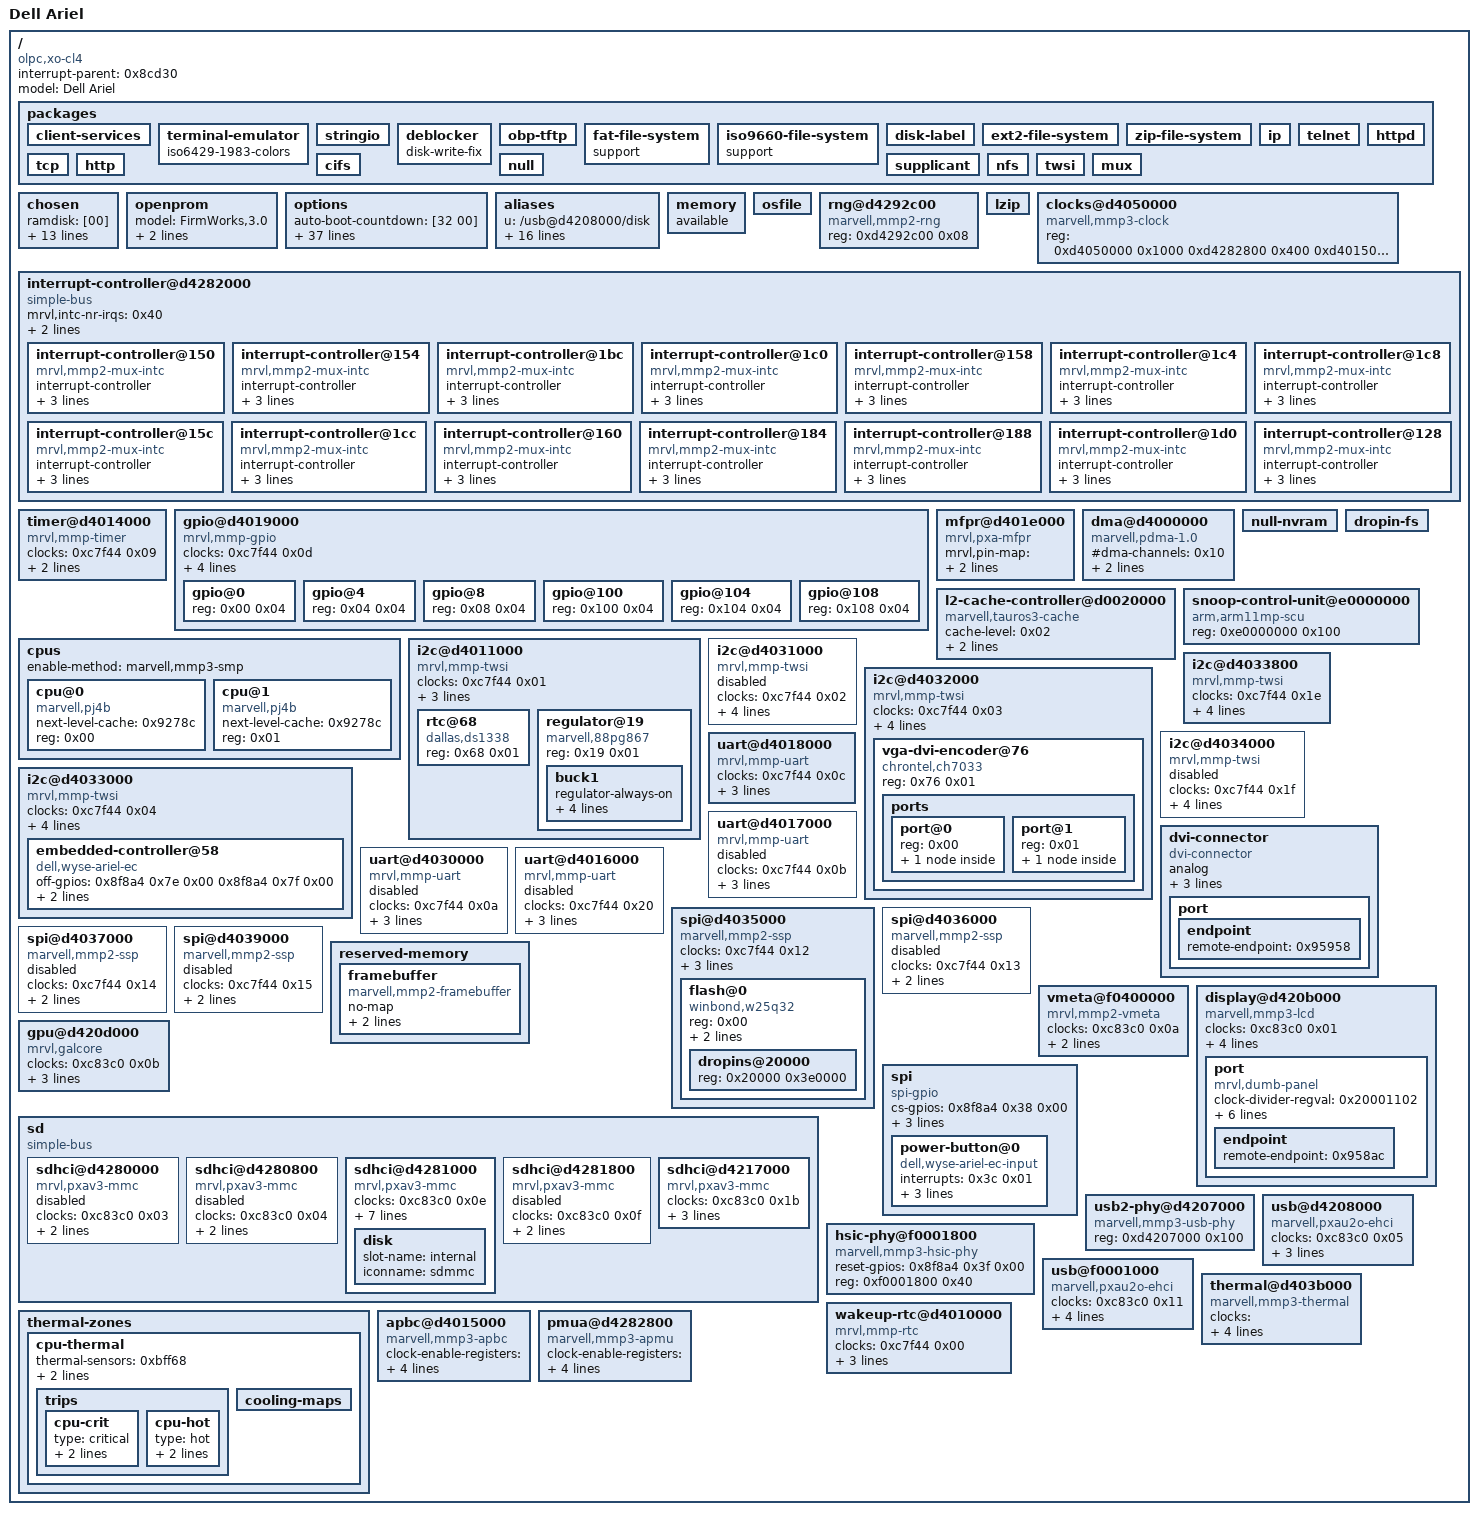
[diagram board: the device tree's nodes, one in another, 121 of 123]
/dts-v1/;

/ {
	phandle = <0x2d294>;
	ranges;
	interrupt-parent = <0x8cd30>;
	compatible = "olpc,xo-cl4\0dell,wyse-ariel\0marvell,mmp3";
	model = "Dell Ariel";
	#size-cells = <0x01>;
	#address-cells = <0x01>;

	packages {
		phandle = <0x313a8>;

		client-services {
			phandle = <0x313dc>;
		};

		terminal-emulator {
			phandle = <0x3c800>;
			iso6429-1983-colors;
		};

		stringio {
			phandle = <0x3f680>;
		};

		deblocker {
			phandle = <0x40a44>;
			disk-write-fix;
		};

		obp-tftp {
			phandle = <0x420f8>;
		};

		fat-file-system {
			phandle = <0x4fd80>;
			support;
		};

		iso9660-file-system {
			phandle = <0x55284>;
			support;
		};

		disk-label {
			phandle = <0x56110>;
		};

		ext2-file-system {
			phandle = <0x5f07c>;
		};

		zip-file-system {
			phandle = <0x65644>;
		};

		ip {
			phandle = <0x69f10>;
		};

		telnet {
			phandle = <0x6cb8c>;
		};

		httpd {
			phandle = <0x6db10>;
		};

		tcp {
			phandle = <0x70740>;
		};

		http {
			phandle = <0x75e9c>;
		};

		cifs {
			phandle = <0x76bb4>;
		};

		supplicant {
			phandle = <0x7a478>;
		};

		null {
			phandle = <0x84554>;
		};

		nfs {
			phandle = <0x84afc>;
		};

		twsi {
			phandle = <0x906b0>;
		};

		mux {
			phandle = <0x91750>;
		};
	};

	chosen {
		phandle = <0x31448>;
		ramdisk = [00];
		cpu = <0x00>;
		root-path = [00];
		vendor-options = [00];
		client-name = [00];
		tftp-file = [00];
		domain-name = [00];
		bootargs = [00];
		bootpath = [00];
		nvram = <0x00>;
		mmu = <0x00>;
		memory = <0x00>;
		clock = <0x00>;
		stdout-#lines = <0x00>;
		#address-cells = <0x01>;
		#size-cells = <0x01>;
		ranges;
	};

	openprom {
		phandle = <0x314ec>;
		model = "FirmWorks,3.0";
		aligned-allocator;
		relative-addressing;
	};

	options {
		phandle = <0x31580>;
		auto-boot-countdown = [32 00];
		ramdisk = [00];
		usb-delay = "350";
		menu? = "true";
		http-proxy = [00];
		client-symbols? = "false";
		fcode-debug? = "true";
		ip-address = "dhcp";
		ip-router = [00];
		ip-domain = [00];
		ip-netmask = "255.255.255.0";
		ip-dns-server = [00];
		local-mac-address? = "true";
		oem-logo;
		oem-logo? = "false";
		oem-banner = [00];
		oem-banner? = "false";
		output-device = "screen";
		input-device = "keyboard";
		load-base = "201326592";
		boot-command = "boot";
		auto-boot? = "true";
		watchdog-reboot? = "false";
		diag-file = [00];
		diag-device = "net";
		boot-file = [00];
		boot-device = "u:\\boot\\olpc.fth int:\\boot\\olpc.fth net";
		ansi-terminal? = "true";
		screen-#columns = "999";
		screen-#rows = "999";
		silent-mode? = "false";
		use-nvramrc? = "false";
		nvramrc = [00];
		security-password;
		security-#badlogins = [30 00];
		security-mode = "none";
		diag-switch? = "false";
	};

	aliases {
		phandle = <0x315cc>;
		u = "/usb@d4208000/disk";
		int = "/sd/sdhci@d4281000/disk";
		screen = "/display";
		dropins = "/dropins";
		serial2 = "/uart@d4018000";
		i2c5 = "/i2c@d4033000";
		i2c4 = "/i2c@d4033800";
		i2c3 = "/i2c@d4032000";
		i2c2 = "/i2c@d4011000";
		rom = "/dropin-fs";
		nfs = "net//obp-tftp:last//nfs";
		cifs = "tcp//cifs";
		smb = "tcp//cifs";
		httpd = "tcp//httpd:verbose";
		http = "tcp//http";
		tcp = "ip//tcp";
		ip = "//ip";
	};

	memory {
		phandle = <0x5d8b4>;
		available;
		device_type = "memory";
	};

	osfile {
		phandle = <0x66a2c>;
	};

	rng@d4292c00 {
		phandle = <0x69730>;
		reg = <0xd4292c00 0x08>;
		compatible = "marvell,mmp2-rng";
	};

	lzip {
		phandle = <0x69cf8>;
	};

	clocks@d4050000 {
		phandle = <0x8c2cc>;
		#power-domain-cells = <0x01>;
		#reset-cells = <0x01>;
		#clock-cells = <0x01>;
		reg-names = "mpmu\0apmu\0apbc";
		reg = <0xd4050000 0x1000 0xd4282800 0x400 0xd4015000 0x1000>;
		compatible = "marvell,mmp3-clock\0marvell,mmp2-clock";
	};

	interrupt-controller@d4282000 {
		phandle = <0x8cd30>;
		mrvl,intc-nr-irqs = <0x40>;
		#interrupt-cells = <0x01>;
		interrupt-controller;
		#size-cells = <0x01>;
		#address-cells = <0x01>;
		ranges;
		compatible = "simple-bus\0mrvl,mmp3-intc\0marvell,mmp3-intc";
		reg = <0xd4282000 0x1000 0xd4284000 0x100>;

		interrupt-controller@150 {
			phandle = <0x8d2e4>;
			reg-names = "mux status\0mux mask";
			#interrupt-cells = <0x01>;
			interrupt-controller;
			compatible = "mrvl,mmp2-mux-intc";
			reg = <0x150 0x04 0x168 0x04>;
			interrupts = <0x04>;
			mrvl,intc-nr-irqs = <0x04>;
		};

		interrupt-controller@154 {
			phandle = <0x8d458>;
			reg-names = "mux status\0mux mask";
			#interrupt-cells = <0x01>;
			interrupt-controller;
			compatible = "mrvl,mmp2-mux-intc";
			reg = <0x154 0x04 0x16c 0x04>;
			interrupts = <0x05>;
			mrvl,intc-nr-irqs = <0x02>;
		};

		interrupt-controller@1bc {
			phandle = <0x8d5cc>;
			reg-names = "mux status\0mux mask";
			#interrupt-cells = <0x01>;
			interrupt-controller;
			compatible = "mrvl,mmp2-mux-intc";
			reg = <0x1bc 0x04 0x1a4 0x04>;
			interrupts = <0x06>;
			mrvl,intc-nr-irqs = <0x03>;
		};

		interrupt-controller@1c0 {
			phandle = <0x8d740>;
			reg-names = "mux status\0mux mask";
			#interrupt-cells = <0x01>;
			interrupt-controller;
			compatible = "mrvl,mmp2-mux-intc";
			reg = <0x1c0 0x04 0x1a8 0x04>;
			interrupts = <0x08>;
			mrvl,intc-nr-irqs = <0x04>;
		};

		interrupt-controller@158 {
			phandle = <0x8d8b4>;
			reg-names = "mux status\0mux mask";
			#interrupt-cells = <0x01>;
			interrupt-controller;
			compatible = "mrvl,mmp2-mux-intc";
			reg = <0x158 0x04 0x170 0x04>;
			interrupts = <0x11>;
			mrvl,intc-nr-irqs = <0x05>;
		};

		interrupt-controller@1c4 {
			phandle = <0x8da28>;
			reg-names = "mux status\0mux mask";
			#interrupt-cells = <0x01>;
			interrupt-controller;
			compatible = "mrvl,mmp2-mux-intc";
			reg = <0x1c4 0x04 0x1ac 0x04>;
			interrupts = <0x12>;
			mrvl,intc-nr-irqs = <0x03>;
		};

		interrupt-controller@1c8 {
			phandle = <0x8db9c>;
			reg-names = "mux status\0mux mask";
			#interrupt-cells = <0x01>;
			interrupt-controller;
			compatible = "mrvl,mmp2-mux-intc";
			reg = <0x1c8 0x04 0x1b0 0x04>;
			interrupts = <0x1e>;
			mrvl,intc-nr-irqs = <0x02>;
		};

		interrupt-controller@15c {
			phandle = <0x8dd10>;
			reg-names = "mux status\0mux mask";
			#interrupt-cells = <0x01>;
			interrupt-controller;
			compatible = "mrvl,mmp2-mux-intc";
			reg = <0x15c 0x04 0x174 0x04>;
			interrupts = <0x23>;
			mrvl,intc-nr-irqs = <0x1f>;
		};

		interrupt-controller@1cc {
			phandle = <0x8de84>;
			reg-names = "mux status\0mux mask";
			#interrupt-cells = <0x01>;
			interrupt-controller;
			compatible = "mrvl,mmp2-mux-intc";
			reg = <0x1cc 0x04 0x1b4 0x04>;
			interrupts = <0x2a>;
			mrvl,intc-nr-irqs = <0x02>;
		};

		interrupt-controller@160 {
			phandle = <0x8dff8>;
			reg-names = "mux status\0mux mask";
			#interrupt-cells = <0x01>;
			interrupt-controller;
			compatible = "mrvl,mmp2-mux-intc";
			reg = <0x160 0x04 0x178 0x04>;
			interrupts = <0x33>;
			mrvl,intc-nr-irqs = <0x02>;
		};

		interrupt-controller@184 {
			phandle = <0x8e16c>;
			reg-names = "mux status\0mux mask";
			#interrupt-cells = <0x01>;
			interrupt-controller;
			compatible = "mrvl,mmp2-mux-intc";
			reg = <0x184 0x04 0x17c 0x04>;
			interrupts = <0x37>;
			mrvl,intc-nr-irqs = <0x04>;
		};

		interrupt-controller@188 {
			phandle = <0x8e2e0>;
			reg-names = "mux status\0mux mask";
			#interrupt-cells = <0x01>;
			interrupt-controller;
			compatible = "mrvl,mmp2-mux-intc";
			reg = <0x188 0x04 0x180 0x04>;
			interrupts = <0x39>;
			mrvl,intc-nr-irqs = <0x14>;
		};

		interrupt-controller@1d0 {
			phandle = <0x8e454>;
			reg-names = "mux status\0mux mask";
			#interrupt-cells = <0x01>;
			interrupt-controller;
			compatible = "mrvl,mmp2-mux-intc";
			reg = <0x1d0 0x04 0x1b8 0x04>;
			interrupts = <0x3a>;
			mrvl,intc-nr-irqs = <0x05>;
		};

		interrupt-controller@128 {
			phandle = <0x8e5c8>;
			reg-names = "mux status\0mux mask";
			#interrupt-cells = <0x01>;
			interrupt-controller;
			compatible = "mrvl,mmp2-mux-intc";
			reg = <0x128 0x04 0x11c 0x04>;
			interrupts = <0x30>;
			mrvl,intc-nr-irqs = <0x18>;
		};
	};

	timer@d4014000 {
		phandle = <0x8f31c>;
		clocks = <0xc7f44 0x09>;
		interrupts = <0x0d>;
		reg = <0xd4014000 0x100>;
		compatible = "mrvl,mmp-timer";
	};

	gpio@d4019000 {
		phandle = <0x8f8a4>;
		clocks = <0xc7f44 0x0d>;
		#size-cells = <0x01>;
		#address-cells = <0x01>;
		clock-names = "GPIO";
		ranges;
		#interrupt-cells = <0x02>;
		interrupt-controller;
		#gpio-cells = <0x02>;
		gpio-controller;
		interrupt-names = "gpio_mux";
		interrupts = <0x31>;
		reg = <0xd4019000 0x1000>;
		compatible = "mrvl,mmp-gpio\0\0marvell,mmp2-gpio";

		gpio@0 {
			phandle = <0x8fb60>;
			reg = <0x00 0x04>;
		};

		gpio@4 {
			phandle = <0x8fbc4>;
			reg = <0x04 0x04>;
		};

		gpio@8 {
			phandle = <0x8fc28>;
			reg = <0x08 0x04>;
		};

		gpio@100 {
			phandle = <0x8fc8c>;
			reg = <0x100 0x04>;
		};

		gpio@104 {
			phandle = <0x8fcf0>;
			reg = <0x104 0x04>;
		};

		gpio@108 {
			phandle = <0x8fd54>;
			reg = <0x108 0x04>;
		};
	};

	mfpr@d401e000 {
		phandle = <0x902ac>;
		mrvl,pin-map = <0x00 0x3a 0x54 0x3b 0x49 0x280 0x4a 0x65 0x170 0x66 0x67 0x00 0x68 0xffffffff 0x1fc 0x69 0xffffffff 0x1f8 0x6a 0xffffffff 0x1f4 0x6b 0xffffffff 0x1f0 0x6c 0xffffffff 0x21c 0x6d 0xffffffff 0x218 0x6e 0xffffffff 0x214 0x6f 0xffffffff 0x200 0x70 0xffffffff 0x244 0x71 0xffffffff 0x25c 0x72 0xffffffff 0x164 0x73 0x7a 0x260 0x7b 0xffffffff 0x148 0x7c 0x8d 0x0c 0x8e 0xffffffff 0x08 0x8f 0x97 0x220 0x98 0x98 0x248 0x9a 0x9b 0x254 0x9c 0x9f 0x14c 0xa0 0xffffffff 0x250 0xa1 0xffffffff 0x210 0xa2 0xffffffff 0x20c 0xa3 0xffffffff 0x208 0xa4 0xffffffff 0x204 0xa5 0xffffffff 0x1ec 0xa6 0xffffffff 0x1e8 0xa7 0xffffffff 0x1e4 0xa8 0xffffffff 0x1e0 0xa9 0xaa 0x2c0 0xab 0xffffffff 0x2c8 0x15b 0x15c 0x140 0x15d 0x15e 0x2bc 0x159 0xffffffff 0x2c4 0x15f 0xffffffff 0x160 0xffffffff 0xffffffff 0xffffffff>;
		compatible = "mrvl,pxa-mfpr";
		reg = <0xd401e000 0x1000>;
	};

	dma@d4000000 {
		phandle = <0x905dc>;
		#dma-channels = <0x10>;
		interrupts = <0x30>;
		compatible = "marvell,pdma-1.0";
		reg = <0xd4000000 0x400>;
	};

	null-nvram {
		phandle = <0x92158>;
	};

	dropin-fs {
		phandle = <0x922e0>;
	};

	l2-cache-controller@d0020000 {
		phandle = <0x9278c>;
		cache-level = <0x02>;
		cache-unified;
		reg = <0xd0020000 0x1000>;
		compatible = "marvell,tauros3-cache\0arm,pl310-cache";
	};

	cpus {
		phandle = <0x928a4>;
		enable-method = "marvell,mmp3-smp";
		#size-cells = <0x00>;
		#address-cells = <0x01>;

		cpu@0 {
			phandle = <0x929b8>;
			next-level-cache = <0x9278c>;
			reg = <0x00>;
			compatible = "marvell,pj4b";
			device_type = "cpu";
		};

		cpu@1 {
			phandle = <0x92ab4>;
			next-level-cache = <0x9278c>;
			reg = <0x01>;
			compatible = "marvell,pj4b";
			device_type = "cpu";
		};
	};

	snoop-control-unit@e0000000 {
		phandle = <0x92c24>;
		reg = <0xe0000000 0x100>;
		compatible = "arm,arm11mp-scu";
	};

	i2c@d4011000 {
		phandle = <0x92e3c>;
		clocks = <0xc7f44 0x01>;
		#size-cells = <0x01>;
		#address-cells = <0x01>;
		reg = <0xd4011000 0x70>;
		interrupts = <0x07>;
		mrvl,i2c-fast-mode;
		compatible = "mrvl,mmp-twsi";

		rtc@68 {
			phandle = <0x94814>;
			reg = <0x68 0x01>;
			compatible = "dallas,ds1338\0idt,idt1338-rtc";
		};

		regulator@19 {
			phandle = <0x94ef8>;
			reg = <0x19 0x01>;
			compatible = "marvell,88pg867";

			buck1 {
				phandle = <0x94ff0>;
				regulator-always-on;
				regulator-boot-on;
				regulator-max-microvolt = <0x1b7740>;
				regulator-min-microvolt = <0x1b7740>;
				regulator-name = "vdd_1v8";
			};
		};
	};

	i2c@d4031000 {
		phandle = <0x93264>;
		clocks = <0xc7f44 0x02>;
		status = "disabled";
		#size-cells = <0x01>;
		#address-cells = <0x01>;
		reg = <0xd4031000 0x70>;
		interrupts = <0x00>;
		interrupt-parent = <0x8d8b4>;
		mrvl,i2c-fast-mode;
		compatible = "mrvl,mmp-twsi";
	};

	i2c@d4032000 {
		phandle = <0x936b4>;
		clocks = <0xc7f44 0x03>;
		#size-cells = <0x01>;
		#address-cells = <0x01>;
		reg = <0xd4032000 0x70>;
		interrupts = <0x01>;
		interrupt-parent = <0x8d8b4>;
		mrvl,i2c-fast-mode;
		compatible = "mrvl,mmp-twsi";

		vga-dvi-encoder@76 {
			phandle = <0x95138>;
			reg = <0x76 0x01>;
			compatible = "chrontel,ch7033";

			ports {
				phandle = <0x95780>;
				#size-cells = <0x00>;
				#address-cells = <0x01>;

				port@0 {
					phandle = <0x95864>;
					reg = <0x00>;

					endpoint {
						phandle = <0x958ac>;
						remote-endpoint = <0x997bc>;
					};
				};

				port@1 {
					phandle = <0x95910>;
					reg = <0x01>;

					endpoint {
						phandle = <0x95958>;
						remote-endpoint = <0x960b4>;
					};
				};
			};
		};
	};

	i2c@d4033000 {
		phandle = <0x93b04>;
		clocks = <0xc7f44 0x04>;
		#size-cells = <0x01>;
		#address-cells = <0x01>;
		reg = <0xd4033000 0x70>;
		interrupts = <0x02>;
		interrupt-parent = <0x8d8b4>;
		mrvl,i2c-fast-mode;
		compatible = "mrvl,mmp-twsi";

		embedded-controller@58 {
			phandle = <0x95a2c>;
			off-gpios = <0x8f8a4 0x7e 0x00 0x8f8a4 0x7f 0x00>;
			system-power-controller;
			reg = <0x58 0x01>;
			compatible = "dell,wyse-ariel-ec\0ene,kb3930";
		};
	};

	i2c@d4033800 {
		phandle = <0x93f54>;
		clocks = <0xc7f44 0x1e>;
		#size-cells = <0x01>;
		#address-cells = <0x01>;
		reg = <0xd4033800 0x70>;
		interrupts = <0x03>;
		interrupt-parent = <0x8d8b4>;
		mrvl,i2c-fast-mode;
		compatible = "mrvl,mmp-twsi";
	};

	i2c@d4034000 {
		phandle = <0x943a4>;
		clocks = <0xc7f44 0x1f>;
		status = "disabled";
		#size-cells = <0x01>;
		#address-cells = <0x01>;
		reg = <0xd4034000 0x70>;
		interrupts = <0x04>;
		interrupt-parent = <0x8d8b4>;
		mrvl,i2c-fast-mode;
		compatible = "mrvl,mmp-twsi";
	};

	dvi-connector {
		phandle = <0x95fa8>;
		analog;
		digital;
		hpd-gpios = <0x8f8a4 0x3e 0x01>;
		ddc-i2c-bus = <0x93f54>;
		compatible = "dvi-connector";

		port {
			phandle = <0x96084>;

			endpoint {
				phandle = <0x960b4>;
				remote-endpoint = <0x95958>;
			};
		};
	};

	uart@d4018000 {
		phandle = <0x96178>;
		clocks = <0xc7f44 0x0c>;
		interrupts = <0x18>;
		reg-shift = <0x02>;
		reg = <0xd4018000 0x20>;
		compatible = "mrvl,mmp-uart\0intel,xscale-uart";
	};

	uart@d4017000 {
		phandle = <0x9636c>;
		clocks = <0xc7f44 0x0b>;
		status = "disabled";
		interrupts = <0x1c>;
		reg-shift = <0x02>;
		reg = <0xd4017000 0x20>;
		compatible = "mrvl,mmp-uart\0intel,xscale-uart";
	};

	uart@d4030000 {
		phandle = <0x96560>;
		clocks = <0xc7f44 0x0a>;
		status = "disabled";
		interrupts = <0x1b>;
		reg-shift = <0x02>;
		reg = <0xd4030000 0x20>;
		compatible = "mrvl,mmp-uart\0intel,xscale-uart";
	};

	uart@d4016000 {
		phandle = <0x96754>;
		clocks = <0xc7f44 0x20>;
		status = "disabled";
		interrupts = <0x2e>;
		reg-shift = <0x02>;
		reg = <0xd4016000 0x20>;
		compatible = "mrvl,mmp-uart\0intel,xscale-uart";
	};

	spi@d4035000 {
		phandle = <0x97cdc>;
		clocks = <0xc7f44 0x12>;
		cs-gpios = <0x8f8a4 0x2e 0x01>;
		compatible = "marvell,mmp2-ssp";
		#size-cells = <0x00>;
		#address-cells = <0x01>;
		reg = <0xd4035000 0x1000>;
		interrupts = <0x00>;

		flash@0 {
			phandle = <0x98304>;
			#address-cells = <0x01>;
			reg = <0x00>;
			m25p,fast-read;
			spi-max-frequency = <0x632ea00>;
			compatible = "winbond,w25q32\0jedec,spi-nor";

			dropins@20000 {
				phandle = <0x98940>;
				reg = <0x20000 0x3e0000>;
			};
		};
	};

	spi@d4036000 {
		phandle = <0x97e5c>;
		clocks = <0xc7f44 0x13>;
		status = "disabled";
		compatible = "marvell,mmp2-ssp";
		#size-cells = <0x00>;
		#address-cells = <0x01>;
		reg = <0xd4036000 0x1000>;
		interrupts = <0x01>;
	};

	spi@d4037000 {
		phandle = <0x97fdc>;
		clocks = <0xc7f44 0x14>;
		status = "disabled";
		compatible = "marvell,mmp2-ssp";
		#size-cells = <0x00>;
		#address-cells = <0x01>;
		reg = <0xd4037000 0x1000>;
		interrupts = <0x14>;
	};

	spi@d4039000 {
		phandle = <0x9815c>;
		clocks = <0xc7f44 0x15>;
		status = "disabled";
		compatible = "marvell,mmp2-ssp";
		#size-cells = <0x00>;
		#address-cells = <0x01>;
		reg = <0xd4039000 0x1000>;
		interrupts = <0x15>;
	};

	reserved-memory {
		phandle = <0x99280>;
		ranges;
		#size-cells = <0x01>;
		#address-cells = <0x01>;

		framebuffer {
			phandle = <0x99318>;
			no-map;
			alignment = <0x2000000>;
			size = <0x2000000>;
			compatible = "marvell,mmp2-framebuffer\0marvell,armada-framebuffer";
		};
	};

	vmeta@f0400000 {
		phandle = <0x99440>;
		clocks = <0xc83c0 0x0a>;
		interrupts = <0x1a>;
		clock-names = "VMETACLK";
		compatible = "mrvl,mmp2-vmeta";
		reg = <0xf0400000 0x400000>;
	};

	display@d420b000 {
		phandle = <0x99640>;
		clock-names = "LCDCLK";
		clocks = <0xc83c0 0x01>;
		iso6429-1983-colors;
		character-set = "ISO8859-1";
		device_type = "display";
		interrupts = <0x29>;
		compatible = "marvell,mmp3-lcd\0marvell,armada-lcdc\0mrvl,pxa168fb";
		reg = <0xd420b000 0x1000>;

		port {
			phandle = <0x9978c>;
			clock-divider-regval = <0x20001102>;
			lcd-pn-ctrl0-regval = <0x8041100>;
			lcd-dumb-ctrl-regval = <0x6000000d>;
			linux,mode-names = "1200x900@50";
			linux,timing-modes = <0x400 0x300 0x32 0x364aed0 0xa0 0x18 0x1d 0x03 0x88 0x06 0x00 0x98 0x73>;
			model = "OLPC DCON panel";
			compatible = "mrvl,dumb-panel";

			endpoint {
				phandle = <0x997bc>;
				remote-endpoint = <0x958ac>;
			};
		};
	};

	gpu@d420d000 {
		phandle = <0x9b5c4>;
		clocks = <0xc83c0 0x0b>;
		clock-names = "GCCLK";
		interrupt-names = "galcore 3D\0galcore 2D";
		interrupt-parent = <0x8d740>;
		interrupts = <0x00 0x02>;
		reg = <0xd420d000 0x1000>;
		compatible = "mrvl,galcore";
	};

	sd {
		phandle = <0x9b718>;
		ranges = <0xd4280000 0xd4280000 0x2000 0xd4217000 0xd4217000 0x800>;
		compatible = "simple-bus\0sdhci";
		#size-cells = <0x01>;
		#address-cells = <0x01>;

		sdhci@d4280000 {
			phandle = <0x9f95c>;
			clocks = <0xc83c0 0x03>;
			status = "disabled";
			#size-cells = <0x00>;
			#address-cells = <0x00>;
			clock-names = "io";
			interrupts = <0x27>;
			compatible = "mrvl,pxav3-mmc\0sdhci-pxav3";
			reg = <0xd4280000 0x800>;
		};

		sdhci@d4280800 {
			phandle = <0xa0068>;
			clocks = <0xc83c0 0x04>;
			status = "disabled";
			#size-cells = <0x00>;
			#address-cells = <0x00>;
			clock-names = "io";
			interrupts = <0x34>;
			compatible = "mrvl,pxav3-mmc\0sdhci-pxav3";
			reg = <0xd4280800 0x800>;
		};

		sdhci@d4281000 {
			phandle = <0xa0774>;
			clocks = <0xc83c0 0x0e>;
			cap-mmc-highspeed;
			bus-width = <0x08>;
			non-removable;
			max-frequency = <0x2faf080>;
			clk-delay-cycles = <0x0f>;
			#size-cells = <0x00>;
			#address-cells = <0x00>;
			clock-names = "io";
			interrupts = <0x35>;
			compatible = "mrvl,pxav3-mmc\0sdhci-pxav3";
			reg = <0xd4281000 0x800>;

			disk {
				phandle = <0xa1e48>;
				slot-name = "internal";
				device_type = "block";
				iconname = "sdmmc";
			};
		};

		sdhci@d4281800 {
			phandle = <0xa0e80>;
			clocks = <0xc83c0 0x0f>;
			status = "disabled";
			#size-cells = <0x00>;
			#address-cells = <0x00>;
			clock-names = "io";
			interrupts = <0x36>;
			compatible = "mrvl,pxav3-mmc\0sdhci-pxav3";
			reg = <0xd4281800 0x800>;
		};

		sdhci@d4217000 {
			phandle = <0xa158c>;
			clocks = <0xc83c0 0x1b>;
			#size-cells = <0x00>;
			#address-cells = <0x00>;
			clock-names = "io";
			interrupts = <0x00>;
			interrupt-parent = <0x8e16c>;
			compatible = "mrvl,pxav3-mmc\0sdhci-pxav3";
			reg = <0xd4217000 0x800>;
		};
	};

	spi {
		phandle = <0xa2c7c>;
		cs-gpios = <0x8f8a4 0x38 0x00>;
		gpio-mosi = <0x8f8a4 0x3a 0x00>;
		gpio-miso = <0x8f8a4 0x39 0x00>;
		gpio-sck = <0x8f8a4 0x37 0x00>;
		#size-cells = <0x00>;
		#address-cells = <0x01>;
		compatible = "spi-gpio";

		power-button@0 {
			phandle = <0xa2e24>;
			interrupts = <0x3c 0x01>;
			interrupt-parent = <0x8f8a4>;
			spi-max-frequency = <0x1f78a40>;
			compatible = "dell,wyse-ariel-ec-input\0ene,kb3930-input";
			reg = <0x00>;
		};
	};

	usb2-phy@d4207000 {
		phandle = <0xa4624>;
		#phy-cells = <0x00>;
		compatible = "marvell,mmp3-usb-phy\0mrvl,mmp3-usb2phy";
		reg = <0xd4207000 0x100>;
	};

	usb@d4208000 {
		phandle = <0xa4a18>;
		clocks = <0xc83c0 0x05>;
		reg-names = "u2o";
		compatible = "marvell,pxau2o-ehci\0usb-ehci";
		device_type = "ehci";
		#size-cells = <0x00>;
		#address-cells = <0x02>;
		phys = <0xa4624>;
		phy-names = "usb";
		interrupts = <0x2c>;
		clock-names = "USBCLK";
		reg = <0xd4208000 0x200>;
	};

	hsic-phy@f0001800 {
		phandle = <0xb1984>;
		reset-gpios = <0x8f8a4 0x3f 0x00>;
		compatible = "marvell,mmp3-hsic-phy";
		#phy-cells = <0x00>;
		reg = <0xf0001800 0x40>;
	};

	usb@f0001000 {
		phandle = <0xb1bc8>;
		clocks = <0xc83c0 0x11>;
		phys = <0xb1984>;
		phy-names = "usb";
		phy_type = "hsic";
		interrupts = <0x16>;
		clock-names = "USBCLK";
		compatible = "marvell,pxau2o-ehci\0usb-ehci";
		device_type = "ehci";
		#size-cells = <0x00>;
		#address-cells = <0x02>;
		reg = <0xf0001000 0x200>;
	};

	thermal@d403b000 {
		phandle = <0xbff68>;
		clocks = <0xc7f44 0x22 0xc7f44 0x24 0xc7f44 0x25 0xc7f44 0x26>;
		clock-names = "THSENS1\0THSENS2\0THSENS3\0THSENS4";
		#thermal-sensor-cells = <0x00>;
		interrupt-parent = <0x8e2e0>;
		interrupts = <0x0b>;
		reg = <0xd403b000 0x1000>;
		compatible = "marvell,mmp3-thermal";
	};

	thermal-zones {
		phandle = <0xc00e8>;

		cpu-thermal {
			phandle = <0xc0120>;
			thermal-sensors = <0xbff68>;
			polling-delay-passive = <0x00>;
			polling-delay = <0x3e8>;

			trips {
				phandle = <0xc01cc>;

				cpu-crit {
					phandle = <0xc01fc>;
					type = "critical";
					hysteresis = <0x00>;
					temperature = <0x18894>;
				};

				cpu-hot {
					phandle = <0xc02a8>;
					type = "hot";
					hysteresis = <0x00>;
					temperature = <0x14c08>;
				};
			};

			cooling-maps {
				phandle = <0xc0368>;
			};
		};
	};

	wakeup-rtc@d4010000 {
		phandle = <0xc39d4>;
		clocks = <0xc7f44 0x00>;
		interrupt-names = "rtc 1Hz\0rtc alarm";
		interrupt-parent = <0x8d458>;
		interrupts = <0x01 0x00>;
		reg = <0xd4010000 0x1000>;
		compatible = "mrvl,mmp-rtc";
	};

	apbc@d4015000 {
		phandle = <0xc7f44>;
		clock-enable-registers = <0x00 0xf7 0x83 0x8000 0x04 0x77 0x03 0x18cba80 0x08 0x77 0x03 0x18cba80 0x0c 0x77 0x03 0x18cba80 0x10 0x77 0x03 0x18cba80 0x14 0x77 0x03 0x18cba80 0x18 0x77 0x03 0x18cba80 0x1c 0x77 0x03 0x18cba80 0x20 0x77 0x03 0x18cba80 0x24 0x77 0x13 0x632ea0 0x2c 0x77 0x13 0x18cba80 0x30 0x77 0x13 0x18cba80 0x34 0x77 0x13 0x18cba80 0x38 0x77 0x03 0x18cba80 0x3c 0x77 0x03 0x18cba80 0x40 0x77 0x03 0x18cba80 0x44 0x77 0x03 0x18cba80 0x48 0x77 0x03 0x18cba80 0x4c 0x77 0x03 0x18cba80 0x50 0x77 0x03 0x18cba80 0x54 0x77 0x03 0x18cba80 0x58 0x77 0x03 0x18cba80 0x5c 0x77 0x03 0x18cba80 0x60 0x77 0x03 0x18cba80 0x64 0x77 0x03 0x18cba80 0x68 0x77 0x03 0x18cba80 0x6c 0x77 0x03 0x18cba80 0x70 0x77 0x03 0x18cba80 0x74 0x77 0x03 0x18cba80 0x78 0x77 0x03 0x18cba80 0x7c 0x77 0x03 0x18cba80 0x80 0x77 0x03 0x18cba80 0x88 0x77 0x13 0x18cba80 0x8c 0x77 0x03 0x18cba80 0x90 0x77 0x03 0x18cba80 0x94 0x07 0x03 0x18cba80 0x98 0x77 0x03 0x18cba80 0x9c 0x77 0x03 0x18cba80 0xa0 0x77 0x03 0x18cba80>;
		clock-output-names = "RTC\0TWSI1\0TWSI2\0TWSI3\0TWSI4\0ONEWIRE\0KPC\0TB_ROTARY\0SW_JTAG\0TIMERS1\0UART1\0UART2\0UART3\0GPIO\0PWM0\0PWM1\0PWM2\0PWM3\0SSP0\0SSP1\0SSP2\0SSP3\0SSP4\0SSP5\0AIB\0ASFAR\0ASSAR\0USIM\0MPMU\0IPC\0TWSI5\0TWSI6\0UART4\0RIPC\0THSENS1\0CORESIGHT\0THSENS2\0THSENS3\0THSENS4";
		#clock-cells = <0x01>;
		reg = <0xd4015000 0x1000>;
		compatible = "marvell,mmp3-apbc\0mrvl,pxa-apbc";
	};

	pmua@d4282800 {
		phandle = <0xc83c0>;
		clock-enable-registers = <0x48 0x19 0x19 0x00 0x4c 0xfffff 0x71b 0x17d78400 0x50 0x3f 0x3f 0x00 0x54 0x1b 0x41b 0xbebc200 0x58 0x1b 0x1b 0xbebc200 0x5c 0x09 0x09 0x1c9c3800 0x60 0x1ff 0xbf 0x5f5e100 0x64 0x09 0x09 0x00 0x68 0x1b 0x1b 0x00 0x6c 0x01 0x01 0x00 0xa4 0x1b 0x1b 0x00 0xcc 0x0f 0x0f 0x00 0xd4 0x1b 0x1b 0x00 0xd8 0x3f 0x3f 0x00 0xe8 0x1b 0x1b 0xbebc200 0xec 0x1b 0x1b 0xbebc200 0xf4 0x3f 0x3f 0x00 0xf8 0x1b 0x1b 0x00 0x100 0x1b 0x1b 0x00 0x108 0x09 0x09 0x00 0x10c 0x13 0x13 0x00 0x110 0x1b 0x1b 0x00 0x120 0x3f 0x3f 0x00 0x124 0x1b 0x1b 0x00 0x134 0x12 0x12 0x00 0x140 0x1b 0x1b 0x00 0x148 0x09 0x09 0x00 0x15c 0x1b 0x1b 0x00 0x164 0x0f 0x0f 0x00 0x18c 0x12 0x12 0x00 0xf8 0x1b 0x1b 0x00 0x104 0x1b 0x1b 0x00 0x210 0x1b 0x1b 0x00>;
		clock-output-names = "IRE\0DISPLAY1\0CCIC\0SDH1\0SDH2\0USB\0NF\0DMA\0WTM\0BUS\0VMETA\0GC\0SMC\0MSPRO\0SDH3\0SDH4\0CCIC2\0HSIC1\0FSIC3\0HSI\0AUDIO\0DISPLAY2\0ISP\0EPD\0APB2\0SPMI\0USB3SS\0SDH5\0DSA\0TPIU\0HSIC2\0SLIM\0FASTENET";
		#clock-cells = <0x01>;
		reg = <0xd4282800 0x1000>;
		compatible = "marvell,mmp3-apmu\0mrvl,pxa-apmu";
	};
};
